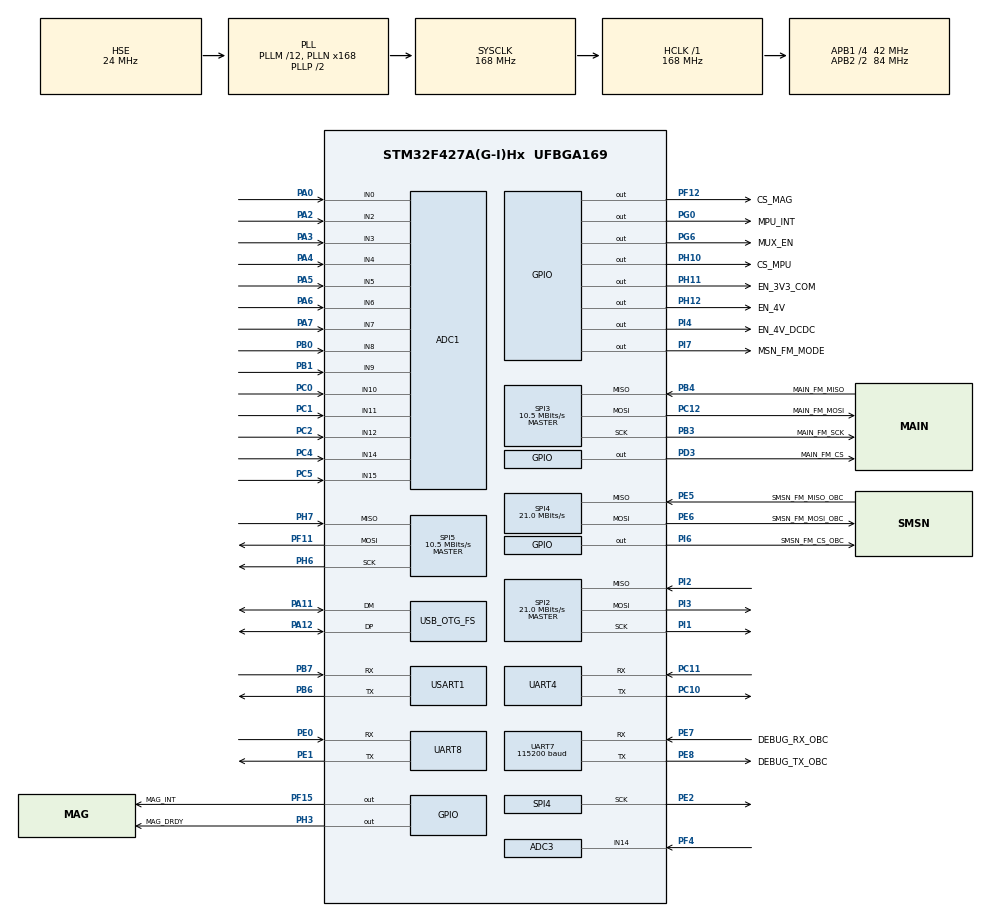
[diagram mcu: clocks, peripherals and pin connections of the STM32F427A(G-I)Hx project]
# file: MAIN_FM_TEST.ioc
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ADC1.Channel-0\#ChannelRegularConversion=ADC_CHANNEL_0
ADC1.NbrOfConversionFlag=1
ADC1.Rank-0\#ChannelRegularConversion=1
ADC1.SamplingTime-0\#ChannelRegularConversion=ADC_SAMPLETIME_3CYCLES
ADC1.master=1
ADC3.Channel-0\#ChannelRegularConversion=ADC_CHANNEL_14
ADC3.NbrOfConversionFlag=1
ADC3.Rank-0\#ChannelRegularConversion=1
ADC3.SamplingTime-0\#ChannelRegularConversion=ADC_SAMPLETIME_3CYCLES
Mcu.Family=STM32F4
Mcu.Name=STM32F427A(G-I)Hx
Mcu.Package=UFBGA169
NVIC.OTG_FS_IRQn=true\:0\:0\:false\:false\:true\:false\:true
NVIC.PriorityGroup=NVIC_PRIORITYGROUP_4
NVIC.UART4_IRQn=true\:0\:0\:false\:false\:true\:true\:true
NVIC.UART7_IRQn=true\:0\:0\:false\:false\:true\:true\:true
NVIC.USART1_IRQn=true\:0\:0\:false\:false\:true\:true\:true
PA0/WKUP.Signal=ADCx_IN0
PA11.Mode=Device_Only
PA11.Signal=USB_OTG_FS_DM
PA12.Mode=Device_Only
PA12.Signal=USB_OTG_FS_DP
PA13.Mode=Serial_Wire
PA13.Signal=SYS_JTMS-SWDIO
PA14.Mode=Serial_Wire
PA14.Signal=SYS_JTCK-SWCLK
PA2.Signal=ADCx_IN2
PA3.Signal=ADCx_IN3
PA4.Signal=ADCx_IN4
PA5.Signal=ADCx_IN5
PA6.Signal=ADCx_IN6
PA7.Signal=ADCx_IN7
PB0.Signal=ADCx_IN8
PB1.Signal=ADCx_IN9
PB3.GPIO_Label=MAIN_FM_SCK
PB3.Mode=Full_Duplex_Master
PB3.Signal=SPI3_SCK
PB4.GPIO_Label=MAIN_FM_MISO
PB4.Mode=Full_Duplex_Master
PB4.Signal=SPI3_MISO
PB6.Mode=Asynchronous
PB6.Signal=USART1_TX
PB7.Mode=Asynchronous
PB7.Signal=USART1_RX
PC0.Signal=ADCx_IN10
PC1.Signal=ADCx_IN11
PC10.Mode=Asynchronous
PC10.Signal=UART4_TX
PC11.Mode=Asynchronous
PC11.Signal=UART4_RX
PC12.GPIO_Label=MAIN_FM_MOSI
PC12.Mode=Full_Duplex_Master
PC12.Signal=SPI3_MOSI
PC14/OSC32_IN.Mode=LSE-External-Oscillator
PC14/OSC32_IN.Signal=RCC_OSC32_IN
PC15/OSC32_OUT.Mode=LSE-External-Oscillator
PC15/OSC32_OUT.Signal=RCC_OSC32_OUT
PC2.Signal=ADCx_IN12
PC4.Signal=ADCx_IN14
PC5.Signal=ADCx_IN15
PD3.GPIO_Label=MAIN_FM_CS
PD3.Signal=GPIO_Output
PE0.Mode=Asynchronous
PE0.Signal=UART8_RX
PE1.Mode=Asynchronous
PE1.Signal=UART8_TX
PE2.Mode=Full_Duplex_Master
PE2.Signal=SPI4_SCK
PE5.GPIO_Label=SMSN_FM_MISO_OBC
PE5.Mode=Full_Duplex_Master
PE5.Signal=SPI4_MISO
PE6.GPIO_Label=SMSN_FM_MOSI_OBC
PE6.Mode=Full_Duplex_Master
PE6.Signal=SPI4_MOSI
PE7.GPIO_Label=DEBUG_RX_OBC
PE7.Mode=Asynchronous
PE7.Signal=UART7_RX
PE8.GPIO_Label=DEBUG_TX_OBC
PE8.Mode=Asynchronous
PE8.Signal=UART7_TX
PF11.Mode=Full_Duplex_Master
PF11.Signal=SPI5_MOSI
PF12.GPIO_Label=CS_MAG
PF12.Signal=GPIO_Output
PF15.GPIO_Label=MAG_INT
PF15.Signal=GPIO_Output
PF4.Mode=IN14
PF4.Signal=ADC3_IN14
PG0.GPIO_Label=MPU_INT
PG0.Signal=GPIO_Output
PG6.GPIO_Label=MUX_EN
PG6.Signal=GPIO_Output
PH0/OSC_IN.Mode=HSE-External-Oscillator
PH0/OSC_IN.Signal=RCC_OSC_IN
PH1/OSC_OUT.Mode=HSE-External-Oscillator
PH1/OSC_OUT.Signal=RCC_OSC_OUT
PH10.GPIO_Label=CS_MPU
PH10.Signal=GPIO_Output
PH11.GPIO_Label=EN_3V3_COM
PH11.Signal=GPIO_Output
PH12.GPIO_Label=EN_4V
PH12.Signal=GPIO_Output
PH3.GPIO_Label=MAG_DRDY
PH3.Signal=GPIO_Output
PH6.Mode=Full_Duplex_Master
PH6.Signal=SPI5_SCK
PH7.Mode=Full_Duplex_Master
PH7.Signal=SPI5_MISO
PI1.Mode=Full_Duplex_Master
PI1.Signal=SPI2_SCK
PI2.Mode=Full_Duplex_Master
PI2.Signal=SPI2_MISO
PI3.Mode=Full_Duplex_Master
PI3.Signal=SPI2_MOSI
PI4.GPIO_Label=EN_4V_DCDC
PI4.Signal=GPIO_Output
PI6.GPIO_Label=SMSN_FM_CS_OBC
PI6.Signal=GPIO_Output
PI7.GPIO_Label=MSN_FM_MODE
PI7.Signal=GPIO_Output
ProjectManager.HeapSize=0x200
ProjectManager.StackSize=0x400
ProjectManager.TargetToolchain=STM32CubeIDE
RCC.48MHZClocksFreq_Value=48000000
RCC.AHBFreq_Value=168000000
RCC.APB1CLKDivider=RCC_HCLK_DIV4
RCC.APB1Freq_Value=42000000
RCC.APB1TimFreq_Value=84000000
RCC.APB2CLKDivider=RCC_HCLK_DIV2
RCC.APB2Freq_Value=84000000
RCC.APB2TimFreq_Value=168000000
RCC.CortexFreq_Value=168000000
RCC.HCLKFreq_Value=168000000
RCC.HSE_VALUE=24000000
RCC.HSI_VALUE=16000000
RCC.PLLM=12
RCC.PLLN=168
RCC.PLLQ=7
RCC.SYSCLKFreq_VALUE=168000000
RCC.SYSCLKSource=RCC_SYSCLKSOURCE_PLLCLK
RCC.VCOOutputFreq_Value=336000000
SH.ADCx_IN0.0=ADC1_IN0,IN0
SH.ADCx_IN10.0=ADC1_IN10,IN10
SH.ADCx_IN11.0=ADC1_IN11,IN11
SH.ADCx_IN12.0=ADC1_IN12,IN12
SH.ADCx_IN14.0=ADC1_IN14,IN14
SH.ADCx_IN15.0=ADC1_IN15,IN15
SH.ADCx_IN2.0=ADC1_IN2,IN2
SH.ADCx_IN3.0=ADC1_IN3,IN3
SH.ADCx_IN4.0=ADC1_IN4,IN4
SH.ADCx_IN5.0=ADC1_IN5,IN5
SH.ADCx_IN6.0=ADC1_IN6,IN6
SH.ADCx_IN7.0=ADC1_IN7,IN7
SH.ADCx_IN8.0=ADC1_IN8,IN8
SH.ADCx_IN9.0=ADC1_IN9,IN9
SPI2.CalculateBaudRate=21.0 MBits/s
SPI2.Direction=SPI_DIRECTION_2LINES
SPI2.Mode=SPI_MODE_MASTER
SPI2.VirtualType=VM_MASTER
SPI3.BaudRatePrescaler=SPI_BAUDRATEPRESCALER_4
SPI3.CalculateBaudRate=10.5 MBits/s
SPI3.Direction=SPI_DIRECTION_2LINES
SPI3.Mode=SPI_MODE_MASTER
SPI3.VirtualType=VM_MASTER
SPI4.BaudRatePrescaler=SPI_BAUDRATEPRESCALER_4
SPI4.CalculateBaudRate=21.0 MBits/s
SPI4.Direction=SPI_DIRECTION_2LINES
SPI4.Mode=SPI_MODE_MASTER
SPI4.VirtualType=VM_MASTER
SPI5.BaudRatePrescaler=SPI_BAUDRATEPRESCALER_8
SPI5.CalculateBaudRate=10.5 MBits/s
SPI5.Direction=SPI_DIRECTION_2LINES
SPI5.Mode=SPI_MODE_MASTER
SPI5.VirtualType=VM_MASTER
TIM6.Prescaler=79
UART4.VirtualMode=Asynchronous
UART7.BaudRate=115200
UART7.VirtualMode=Asynchronous
UART8.VirtualMode=Asynchronous
USART1.VirtualMode=VM_ASYNC
USB_DEVICE.CLASS_NAME_FS=CDC
USB_DEVICE.VirtualMode-CDC_FS=Cdc
USB_DEVICE.VirtualModeFS=Cdc_FS
USB_OTG_FS.VirtualMode=Device_Only
VP_TIM6_VS_ClockSourceINT.Mode=Enable_Timer
VP_TIM7_VS_ClockSourceINT.Mode=Enable_Timer
VP_TIM9_VS_ClockSourceINT.Mode=Internal
VP_USB_DEVICE_VS_USB_DEVICE_CDC_FS.Mode=CDC_FS
board=custom

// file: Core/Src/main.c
/* USER CODE BEGIN Header */
/**
  ******************************************************************************
  * @file           : main.c
  * @brief          : Main program body
  ******************************************************************************
  * @attention
  *
  * <h2><center>&copy; Copyright (c) 2024 STMicroelectronics.
  * All rights reserved.</center></h2>
  *
  * This software component is licensed by ST under Ultimate Liberty license
  * SLA0044, the "License"; You may not use this file except in compliance with
  * the License. You may obtain a copy of the License at:
  *                             www.st.com/SLA0044
  *
  ******************************************************************************
  */
/* USER CODE END Header */
#include "main.h"
#include "adc.h"
#include "spi.h"
#include "tim.h"
#include "usart.h"
#include "usb_device.h"
#include "gpio.h"

/* USER CODE BEGIN Includes */
#include "variables.h"
#include "../../Core/Drivers/flash/MT25QL.h"
#include "../../Core/Drivers/flash/internal_flash.h"
#include "../../Core/Drivers/flash/memory_addressing.h"
#include "imu.h"
/* USER CODE END Includes */

/* USER CODE BEGIN PM */
//void Read_ID(SPI_HandleTypeDef *SPI, uint8_t data[20]);
//static void FM_Enable(SPI_HandleTypeDef *SPI);
//static void FM_Disable(SPI_HandleTypeDef *SPI);

/* USER CODE END PM */

/* USER CODE BEGIN PV */

  DEVICE_ID rxData;
uint8_t counter = 0;
//uint8_t SFM[20];
const uint32_t address = 0x08000300;
uint8_t read_buff[4];
uint8_t buffer[4] =  {0x02,0x04,0x06,0x08 };
MPU6500_t pMPU6500;

/* USER CODE END PV */

void SystemClock_Config(void);

int main(void)
{

  /* MCU Configuration--------------------------------------------------------*/

  /* Reset of all peripherals, Initializes the Flash interface and the Systick. */
  HAL_Init();

  /* USER CODE BEGIN Init */
  HAL_GPIO_WritePin(GPIOI, GPIO_PIN_6, GPIO_PIN_SET);

  /* USER CODE END Init */

  /* Configure the system clock */
  SystemClock_Config();

  /* Initialize all configured peripherals */
  MX_GPIO_Init();
  MX_SPI3_Init();
  MX_UART7_Init();
  MX_USB_DEVICE_Init();
  MX_SPI4_Init();
  MX_USART1_UART_Init();
  MX_ADC1_Init();
  MX_ADC3_Init();
  MX_SPI5_Init();
  MX_UART4_Init();
  MX_TIM6_Init();
  MX_UART8_Init();
  MX_TIM7_Init();
  MX_TIM9_Init();
  MX_SPI2_Init();
  /* USER CODE BEGIN 2 */
//  Sector_Erase(&hspi4, address, 4);
//  Sector_Erase(&hspi3, address, 4);
//  for(int i=8;i<24;i++)
//  ERASE_INTERNAL_FLASH(i);
//  HK_IMU();
//  HK_IMU();
//  HAL_TIM_Base_Start(&htim6);
  uint8_t pData[] = "S2S OBC Running\n";

//  uint8_t beg = MPU_begin(&hspi2, &pMPU6500);

//  for(int i=0 ; i < 9; i++){
//		   		  Byte_Write_4B(&hspi4, address+i, i+30);
//		   		HAL_Delay(200);
//		   		  Byte_Write_4B(&hspi3, address+i, i+30);
//		   	  }
//		  	  HAL_Delay(1000);
//		  	 for(int i=0 ; i < 9; i++){
//		  	   		  SFM[i] = Read_Byte_4B(&hspi4, address+i);
//		  	   		  HAL_Delay(200);
//		  	   		  FM[i] = Read_Byte_4B(&hspi3, address+i);
//		  	   	  }
//  ERASE_INTERNAL_FLASH(22);

  HK_IMU();
  /* USER CODE END 2 */

  /* Infinite loop */
  /* USER CODE BEGIN WHILE */
  while (1)
  {
//	  HK_IMU();
//	  HAL_Delay(2000);
//	  Read_ID(&hspi3, &rxData);
//	  WRITE_TO_INTERNAL_FLASH(22, address, buffer, 4);
//	  READ_FRM_INTERNAL_FLASH(address, read_buff, 4);
//	  READ_FRM_INTERNAL_FLASH(address, buffer, 4);
//	  HAL_UART_Transmit(&huart7, pData, 12, 100);
//	  HAL_Delay(1000);
//	  IMU_Setup();
//	  IMU_Data();

//		IMU_Setup();

    /* USER CODE END WHILE */

  }
}

void SystemClock_Config(void)
{
  RCC_OscInitTypeDef RCC_OscInitStruct = {0};
  RCC_ClkInitTypeDef RCC_ClkInitStruct = {0};

  /** Configure the main internal regulator output voltage
  */
  __HAL_RCC_PWR_CLK_ENABLE();
  __HAL_PWR_VOLTAGESCALING_CONFIG(PWR_REGULATOR_VOLTAGE_SCALE1);
  /** Initializes the RCC Oscillators according to the specified parameters
  * in the RCC_OscInitTypeDef structure.
  */
  RCC_OscInitStruct.OscillatorType = RCC_OSCILLATORTYPE_HSE;
  RCC_OscInitStruct.HSEState = RCC_HSE_ON;
  RCC_OscInitStruct.PLL.PLLState = RCC_PLL_ON;
  RCC_OscInitStruct.PLL.PLLSource = RCC_PLLSOURCE_HSE;
  RCC_OscInitStruct.PLL.PLLM = 12;
  RCC_OscInitStruct.PLL.PLLN = 168;
  RCC_OscInitStruct.PLL.PLLP = RCC_PLLP_DIV2;
  RCC_OscInitStruct.PLL.PLLQ = 7;
  if (HAL_RCC_OscConfig(&RCC_OscInitStruct) != HAL_OK)
  {
    Error_Handler();
  }
  /** Initializes the CPU, AHB and APB buses clocks
  */
  RCC_ClkInitStruct.ClockType = RCC_CLOCKTYPE_HCLK|RCC_CLOCKTYPE_SYSCLK
                              |RCC_CLOCKTYPE_PCLK1|RCC_CLOCKTYPE_PCLK2;
  RCC_ClkInitStruct.SYSCLKSource = RCC_SYSCLKSOURCE_PLLCLK;
  RCC_ClkInitStruct.AHBCLKDivider = RCC_SYSCLK_DIV1;
  RCC_ClkInitStruct.APB1CLKDivider = RCC_HCLK_DIV4;
  RCC_ClkInitStruct.APB2CLKDivider = RCC_HCLK_DIV2;

  if (HAL_RCC_ClockConfig(&RCC_ClkInitStruct, FLASH_LATENCY_5) != HAL_OK)
  {
    Error_Handler();
  }
}

/* USER CODE BEGIN 4 */

//void Read_ID(SPI_HandleTypeDef *SPI, uint8_t data[20]) {
//	uint8_t cmd = 0x9E;
//	FM_Enable(SPI);
//	HAL_Delay(1);
//	HAL_SPI_Transmit(SPI, &cmd, 1, 300);
//	HAL_SPI_Receive(SPI, data, 20, 2000);
//	HAL_Delay(1);
//	FM_Disable(SPI);
//	HAL_Delay(500);
////	buff.MAN_ID = data[0];
////	buff.M_TYPE = data[1];
////	buff.M_CAP = data[2];
////	buff.REM_BYTES = data[3];
////	buff.EXT_ID = data[4];
////	buff.DEV_INFO = data[5];
////	for (int i = 6; i < 20; i++) {
////		buff.UID[i] = data[i];
////	}
//
//}
//static void FM_Enable(SPI_HandleTypeDef *SPI) {
//		HAL_GPIO_WritePin(GPIOD, GPIO_PIN_3, GPIO_PIN_RESET);
//
//}
//
//static void FM_Disable(SPI_HandleTypeDef *SPI) {
//	HAL_GPIO_WritePin(GPIOD, GPIO_PIN_3, GPIO_PIN_SET);
//
//}

/* USER CODE END 4 */

void Error_Handler(void)
{
  __disable_irq();
  while (1)
  {
  }
}

/************************ (C) COPYRIGHT STMicroelectronics *****END OF FILE****/
